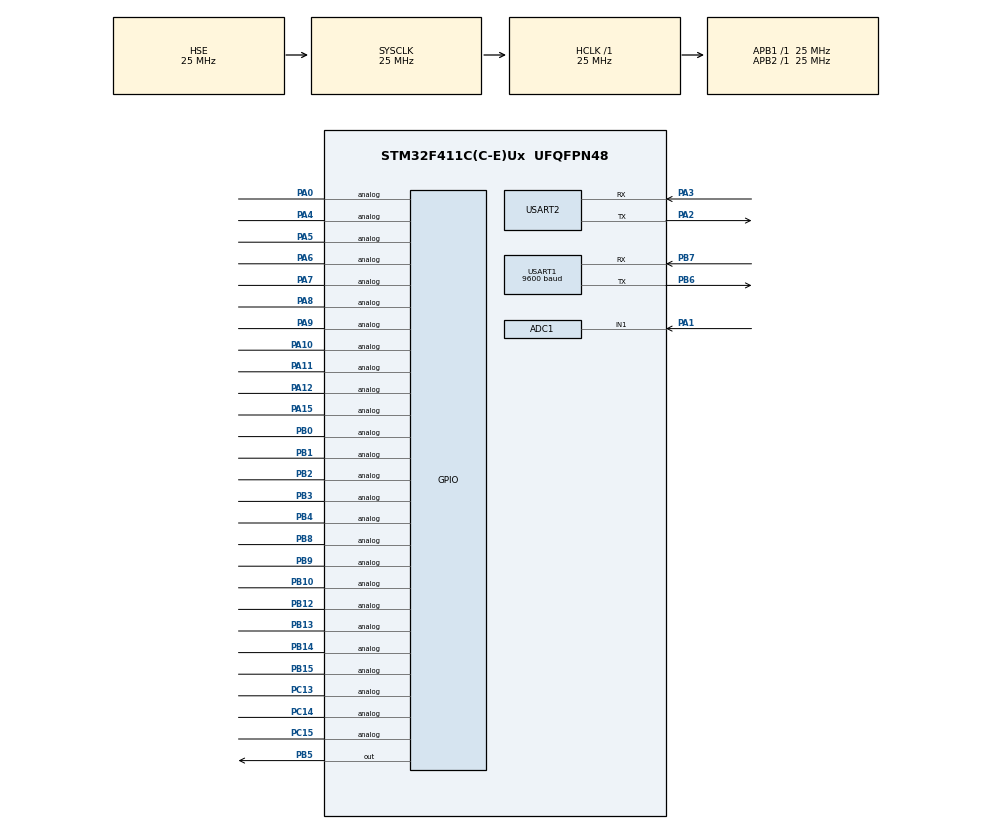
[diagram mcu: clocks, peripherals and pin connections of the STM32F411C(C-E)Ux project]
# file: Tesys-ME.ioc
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ADC1.Channel-0\#ChannelRegularConversion=ADC_CHANNEL_1
ADC1.ClockPrescaler=ADC_CLOCK_SYNC_PCLK_DIV4
ADC1.NbrOfConversionFlag=1
ADC1.Rank-0\#ChannelRegularConversion=1
ADC1.SamplingTime-0\#ChannelRegularConversion=ADC_SAMPLETIME_3CYCLES
ADC1.master=1
IWDG.Prescaler=IWDG_PRESCALER_256
Mcu.Family=STM32F4
Mcu.Name=STM32F411C(C-E)Ux
Mcu.Package=UFQFPN48
NVIC.ADC_IRQn=true\:0\:0\:false\:false\:true\:true\:true
NVIC.PriorityGroup=NVIC_PRIORITYGROUP_4
NVIC.USART1_IRQn=true\:0\:0\:false\:false\:true\:true\:true
NVIC.USART2_IRQn=true\:0\:0\:false\:false\:true\:true\:true
PA0-WKUP.Signal=GPIO_Analog
PA1.Signal=ADCx_IN1
PA10.Signal=GPIO_Analog
PA11.Signal=GPIO_Analog
PA12.Signal=GPIO_Analog
PA13.Mode=Serial_Wire
PA13.Signal=SYS_JTMS-SWDIO
PA14.Mode=Serial_Wire
PA14.Signal=SYS_JTCK-SWCLK
PA15.Signal=GPIO_Analog
PA2.Mode=Asynchronous
PA2.Signal=USART2_TX
PA3.Mode=Asynchronous
PA3.Signal=USART2_RX
PA4.Signal=GPIO_Analog
PA5.Signal=GPIO_Analog
PA6.Signal=GPIO_Analog
PA7.Signal=GPIO_Analog
PA8.Signal=GPIO_Analog
PA9.Signal=GPIO_Analog
PB0.Signal=GPIO_Analog
PB1.Signal=GPIO_Analog
PB10.Signal=GPIO_Analog
PB12.Signal=GPIO_Analog
PB13.Signal=GPIO_Analog
PB14.Signal=GPIO_Analog
PB15.Signal=GPIO_Analog
PB2.Signal=GPIO_Analog
PB3.Signal=GPIO_Analog
PB4.Signal=GPIO_Analog
PB5.Signal=GPIO_Output
PB6.Mode=Asynchronous
PB6.Signal=USART1_TX
PB7.Mode=Asynchronous
PB7.Signal=USART1_RX
PB8.Signal=GPIO_Analog
PB9.Signal=GPIO_Analog
PC13-ANTI_TAMP.Signal=GPIO_Analog
PC14-OSC32_IN.Signal=GPIO_Analog
PC15-OSC32_OUT.Signal=GPIO_Analog
PH0\ -\ OSC_IN.Mode=HSE-External-Oscillator
PH0\ -\ OSC_IN.Signal=RCC_OSC_IN
PH1\ -\ OSC_OUT.Mode=HSE-External-Oscillator
PH1\ -\ OSC_OUT.Signal=RCC_OSC_OUT
ProjectManager.HeapSize=0x200
ProjectManager.StackSize=0x400
ProjectManager.TargetToolchain=STM32CubeIDE
RCC.AHBFreq_Value=25000000
RCC.APB1Freq_Value=25000000
RCC.APB1TimFreq_Value=25000000
RCC.APB2Freq_Value=25000000
RCC.APB2TimFreq_Value=25000000
RCC.CortexFreq_Value=25000000
RCC.HCLKFreq_Value=25000000
RCC.HSE_VALUE=25000000
RCC.HSI_VALUE=16000000
RCC.LSE_VALUE=32768
RCC.SYSCLKFreq_VALUE=25000000
RCC.SYSCLKSource=RCC_SYSCLKSOURCE_HSE
RCC.VCOOutputFreq_Value=192000000
SH.ADCx_IN1.0=ADC1_IN1,IN1
USART1.BaudRate=9600
USART1.VirtualMode=VM_ASYNC
USART2.VirtualMode=VM_ASYNC
VP_IWDG_VS_IWDG.Mode=IWDG_Activate
board=custom

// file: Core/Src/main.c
/* USER CODE BEGIN Header */
/**
  ******************************************************************************
  * @file           : main.c
  * @brief          : Main program body
  ******************************************************************************
  * @attention
  *
  * <h2><center>&copy; Copyright (c) 2022 STMicroelectronics.
  * All rights reserved.</center></h2>
  *
  * This software component is licensed by ST under BSD 3-Clause license,
  * the "License"; You may not use this file except in compliance with the
  * License. You may obtain a copy of the License at:
  *                        opensource.org/licenses/BSD-3-Clause
  *
  ******************************************************************************
  */
/* USER CODE END Header */
#include "main.h"
#include "adc.h"
#include "iwdg.h"
#include "usart.h"
#include "gpio.h"

/* USER CODE BEGIN Includes */
#include "ac_app.h"
/* USER CODE END Includes */

void SystemClock_Config(void);

int main(void)
{

  /* MCU Configuration--------------------------------------------------------*/

  /* Reset of all peripherals, Initializes the Flash interface and the Systick. */
  HAL_Init();

  /* Configure the system clock */
  SystemClock_Config();

  /* Initialize all configured peripherals */
  MX_GPIO_Init();
  MX_ADC1_Init();
  MX_USART1_UART_Init();
  MX_USART2_UART_Init();
  MX_IWDG_Init();
  /* USER CODE BEGIN 2 */

  App_Start();

  /* USER CODE END 2 */

  /* Infinite loop */
  while (1)
  {

  }
}

void SystemClock_Config(void)
{
  RCC_OscInitTypeDef RCC_OscInitStruct = {0};
  RCC_ClkInitTypeDef RCC_ClkInitStruct = {0};

  /** Configure the main internal regulator output voltage
  */
  __HAL_RCC_PWR_CLK_ENABLE();
  __HAL_PWR_VOLTAGESCALING_CONFIG(PWR_REGULATOR_VOLTAGE_SCALE1);
  /** Initializes the RCC Oscillators according to the specified parameters
  * in the RCC_OscInitTypeDef structure.
  */
  RCC_OscInitStruct.OscillatorType = RCC_OSCILLATORTYPE_LSI|RCC_OSCILLATORTYPE_HSE;
  RCC_OscInitStruct.HSEState = RCC_HSE_ON;
  RCC_OscInitStruct.LSIState = RCC_LSI_ON;
  RCC_OscInitStruct.PLL.PLLState = RCC_PLL_NONE;
  if (HAL_RCC_OscConfig(&RCC_OscInitStruct) != HAL_OK)
  {
    Error_Handler();
  }
  /** Initializes the CPU, AHB and APB buses clocks
  */
  RCC_ClkInitStruct.ClockType = RCC_CLOCKTYPE_HCLK|RCC_CLOCKTYPE_SYSCLK
                              |RCC_CLOCKTYPE_PCLK1|RCC_CLOCKTYPE_PCLK2;
  RCC_ClkInitStruct.SYSCLKSource = RCC_SYSCLKSOURCE_HSE;
  RCC_ClkInitStruct.AHBCLKDivider = RCC_SYSCLK_DIV1;
  RCC_ClkInitStruct.APB1CLKDivider = RCC_HCLK_DIV1;
  RCC_ClkInitStruct.APB2CLKDivider = RCC_HCLK_DIV1;

  if (HAL_RCC_ClockConfig(&RCC_ClkInitStruct, FLASH_LATENCY_0) != HAL_OK)
  {
    Error_Handler();
  }
}

void Error_Handler(void)
{
  __disable_irq();
  while (1)
  {
  }
}

/************************ (C) COPYRIGHT STMicroelectronics *****END OF FILE****/
